# STM32U599xx register map
File version: 1.0
Registers are 32-bit, read-write, reset 0x0 unless marked. A register's access mark holds for its fields unless they carry their own. Offsets are from the block's base; [hi:lo] are bit positions; {n}, {i} and the like mark numbered series; 'fields as' and 'values as' point back to an identical list.

## COMP1 — Comparator
Base 0x46005400; alternate view of COMP12
Same registers: COMP2 0x46005404, COMP1_S 0x56005400 (alternate view of COMP12_S), COMP2_S 0x56005404
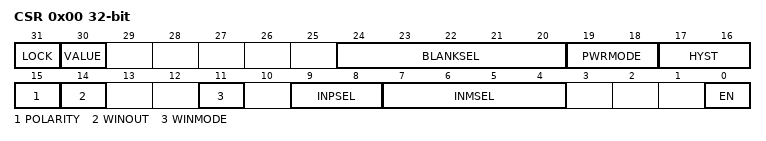
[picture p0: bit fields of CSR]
0x00 CSR — Comparator control and status register
  [31] LOCK — Comparator lock
  [30] VALUE — Comparator output level
  [24:20] BLANKSEL — Comparator blanking source
    0=NONE (Comparator output without blanking); 1=TIM1_OC5 (Comparator output blanking source TIM1 OC5 for COMP1 Instance); 2=TIM2_OC3 (Comparator output blanking source TIM2 OC3 for COMP1 Instance); 4=TIM3_OC3 (Comparator output blanking source TIM3 OC3 for COMP1 Instance)
  [19:18] PWRMODE — Comparator power mode
    0=HIGHSPEED (COMP power mode to high speed); 1=MEDIUMSPEED (COMP power mode to medium speed); 3=ULTRALOWPOWER (COMP power mode to ultra-low power)
  [17:16] HYST — Comparator input hysteresis
    0=NONE (No hysteresis); 1=LOW (Hysteresis level low); 2=MEDIUM (Hysteresis level medium); 3=HIGH (Hysteresis level high)
  [15] POLARITY — Comparator output polarity
    0=NONINVERTED (COMP output polarity is not inverted: comparator output is high when the plus (non-inverting) input is at a higher voltage than the minus (inverting) input); 1=INVERTED (COMP output polarity is inverted: comparator output is low when the plus (non-inverting) input is at a lower voltage than the minus (inverting) input)
  [14] WINOUT — Pair of comparators window output level. Bit intended to be used with COMP common instance (COMP_Common_TypeDef)
  [11] WINMODE — Pair of comparators window mode. Bit intended to be used with COMP common instance (COMP_Common_TypeDef)
  [9:8] INPSEL — Comparator input plus selection
    0=IO1 (Comparator input plus connected to IO1 (pin PC5 for COMP1, pin PB4 for COMP2)); 1=IO2 (Comparator input plus connected to IO2 (pin PB2 for COMP1, pin PB6 for COMP2)); 2=IO3 (Comparator input plus connected to IO3 (pin PA2 for COMP1))
  [7:4] INMSEL — Comparator input minus selection
    0=MINUS_1_4VREFINT (Comparator input minus connected to 1/4 VrefInt); 1=MINUS_1_2VREFINT (Comparator input minus connected to 1/2 VrefInt); 2=MINUS_3_4VREFINT (Comparator input minus connected to 3/4 VrefInt); 3=VREFINT (Comparator input minus connected to VrefInt); 4=DAC1_CH1 (Comparator input minus connected to DAC1 channel 1 (DAC_OUT1)); 5=DAC1_CH2 (Comparator input minus connected to DAC1 channel 2 (DAC_OUT2)); 6=IO1 (Comparator input minus connected to IO1 (pin PB1 for COMP1, pin PB3 for COMP2)); 7=IO2 (Comparator input minus connected to IO2 (pin PC4 for COMP1, pin PB7 for COMP2))
  [0] EN — Comparator enable

## VREFBUF
Base 0x46007400
Same registers: VREFBUF_S 0x56007400
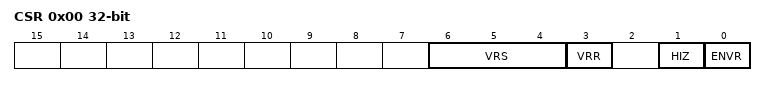
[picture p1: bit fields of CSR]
0x00 CSR — VREFBUF control and status register
  [6:4] VRS — Voltage reference scale
    {v}=SCALE{v} (Voltage reference scale {v} (VREF_OUT{v+1})) (v=0..3)
  [3] VRR — Voltage reference buffer ready
  [1] HIZ — High impedance mode
  [0] ENVR — Voltage reference buffer enable
0x04 CCR — VREFBUF calibration and control register
  [5:0] TRIM — TRIM[5:0] bits (Trimming code)

## EXTI — Asynch Interrupt/Event Controller (EXTI)
Base 0x46022000
Same registers: EXTI_S 0x56022000
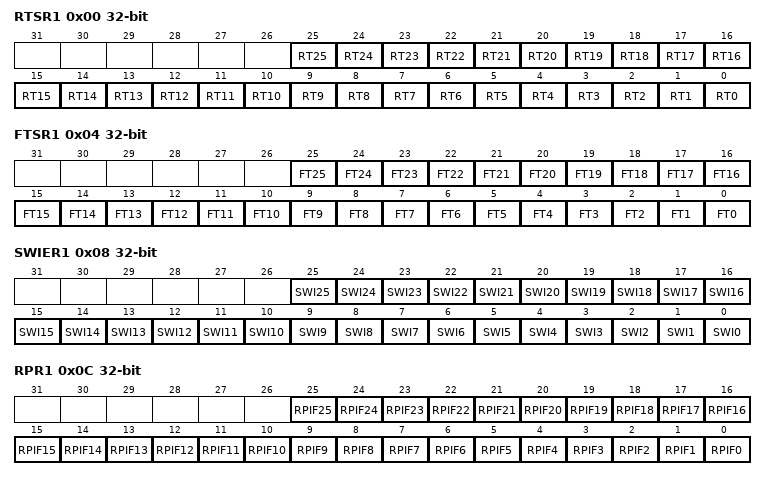
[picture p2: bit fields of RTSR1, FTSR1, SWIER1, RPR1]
0x00 RTSR1 — EXTI Rising Trigger Selection Register 1
  [25] RT25 — Rising trigger configuration for input line 24
  [n] RT{n} (n=0..24) — Rising trigger configuration for input line {n}
0x04 FTSR1 — EXTI Falling Trigger Selection Register 1
  [n] FT{n} (n=0..25) — Falling trigger configuration for input line {n}
0x08 SWIER1 — EXTI Software Interrupt event Register 1
  [n] SWI{n} (n=0..25) — Software Interrupt on line {n}
0x0C RPR1 — EXTI Rising Pending Register 1
  [n] RPIF{n} (n=0..25) — Rising Pending Interrupt Flag on line {n}
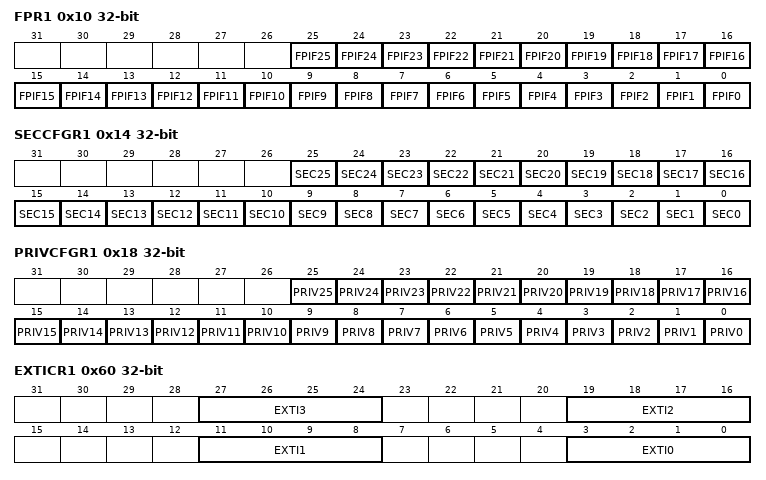
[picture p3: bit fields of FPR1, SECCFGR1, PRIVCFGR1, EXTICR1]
0x10 FPR1 — EXTI Falling Pending Register 1
  [n] FPIF{n} (n=0..25) — Falling Pending Interrupt Flag on line {n}
0x14 SECCFGR1 — EXTI Security Configuration Register 1
  [n] SEC{n} (n=0..25) — Security enable on line {n}
0x18 PRIVCFGR1 — EXTI Privilege Configuration Register 1
  [n] PRIV{n} (n=0..25) — Privilege enable on line {n}
0x60 EXTICR1 — EXIT External Interrupt Configuration Register, 0x60 -- 0x6C
  [8n+3:8n] EXTI{n} (n=0..3) — EXTI {n} configuration
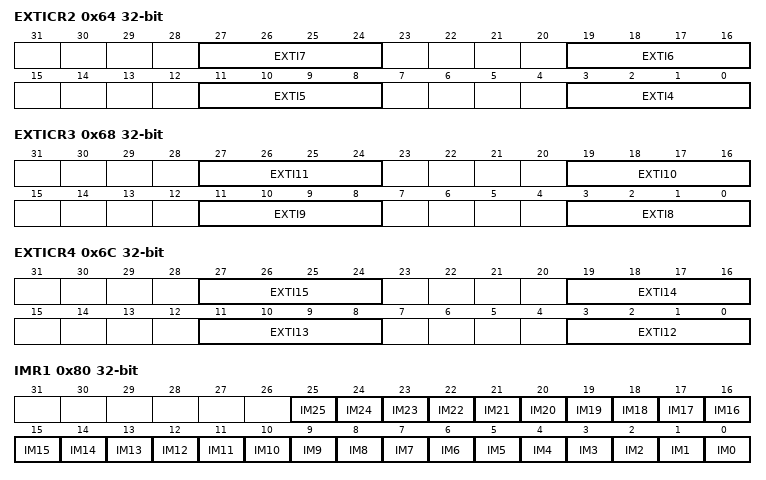
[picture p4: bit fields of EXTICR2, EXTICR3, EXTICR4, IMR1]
0x64 EXTICR2 — EXIT External Interrupt Configuration Register, 0x60 -- 0x6C
  [8n-29:8n-32] EXTI{n} (n=4..7) — EXTI {n} configuration
0x68 EXTICR3 — EXIT External Interrupt Configuration Register, 0x60 -- 0x6C
  [8n-61:8n-64] EXTI{n} (n=8..11) — EXTI {n} configuration
0x6C EXTICR4 — EXIT External Interrupt Configuration Register, 0x60 -- 0x6C
  [8n-93:8n-96] EXTI{n} (n=12..15) — EXTI {n} configuration
0x70 LOCKR — EXTI Lock Register
  [0] LOCK — Global security and privilege configuration registers lock
0x80 IMR1 — EXTI Interrupt Mask Register 1
  [n] IM{n} (n=0..25) — Interrupt Mask on line {n}
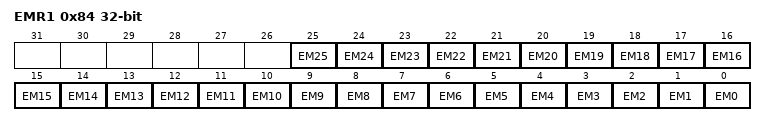
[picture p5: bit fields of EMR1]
0x84 EMR1 — EXTI Event Mask Register 1
  [n] EM{n} (n=0..25) — Event Mask on line {n}

## GTZC_TZIC2
Base 0x46023400
Same registers: GTZC_TZIC2_S 0x56023400
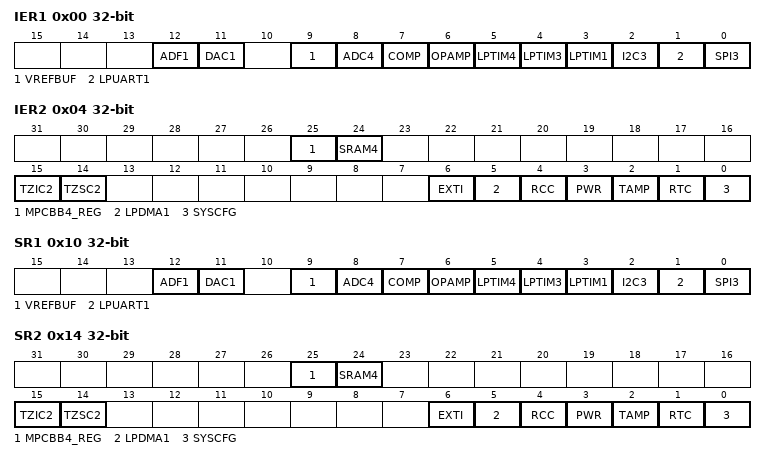
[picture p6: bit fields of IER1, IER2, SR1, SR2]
0x00 IER1 — TZIC interrupt enable register 1
  [12] ADF1, [11] DAC1, [9] VREFBUF, [8] ADC4, [7] COMP, [6] OPAMP, [5] LPTIM4, [4] LPTIM3, [3] LPTIM1, [2] I2C3, [1] LPUART1, [0] SPI3
0x04 IER2 — TZIC interrupt enable register 2
  [25] MPCBB4_REG, [24] SRAM4, [15] TZIC2, [14] TZSC2, [6] EXTI, [5] LPDMA1, [4] RCC, [3] PWR, [2] TAMP, [1] RTC, [0] SYSCFG
0x08 IER3 — TZIC interrupt enable register 3
0x0C IER4 — TZIC interrupt enable register 4
0x10 SR1 — TZIC status register 1
  fields as IER1
0x14 SR2 — TZIC status register 2
  fields as IER2
0x18 SR3 — TZIC status register 3
0x1C SR4 — TZIC status register 4
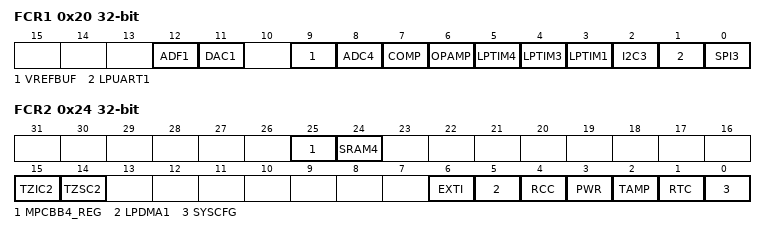
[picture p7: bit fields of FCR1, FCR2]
0x20 FCR1 — TZIC flag clear register 1
  fields as IER1
0x24 FCR2 — TZIC flag clear register 2
  fields as IER2
0x28 FCR3 — TZIC flag clear register 3
0x2C FCR4 — TZIC flag clear register 3

## DBGMCU — Debug MCU
Base 0xE0044000
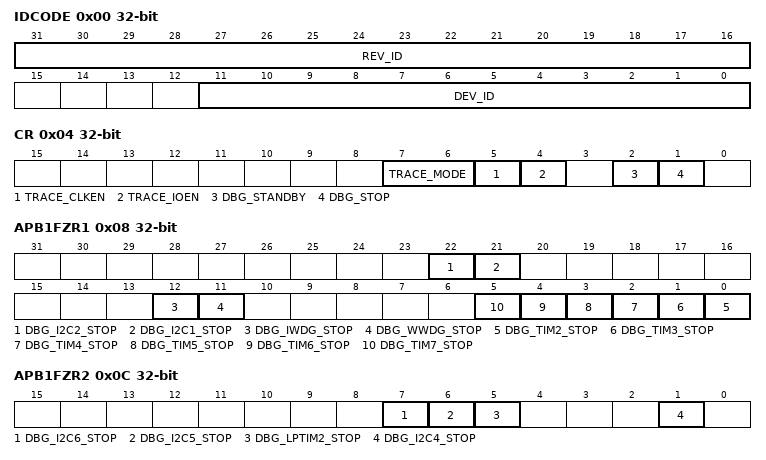
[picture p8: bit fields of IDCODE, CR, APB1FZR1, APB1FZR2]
0x00 IDCODE — MCU device ID code
  [31:16] REV_ID, [11:0] DEV_ID
0x04 CR — Debug MCU configuration register
  [7:6] TRACE_MODE, [5] TRACE_CLKEN, [4] TRACE_IOEN, [2] DBG_STANDBY, [1] DBG_STOP
0x08 APB1FZR1 — Debug MCU APB1 freeze register 1
  [22] DBG_I2C2_STOP, [21] DBG_I2C1_STOP, [12] DBG_IWDG_STOP, [11] DBG_WWDG_STOP, [n-2] DBG_TIM{n}_STOP (n=2..7)
0x0C APB1FZR2 — Debug MCU APB1 freeze register 2
  [7] DBG_I2C6_STOP, [6] DBG_I2C5_STOP, [5] DBG_LPTIM2_STOP, [1] DBG_I2C4_STOP
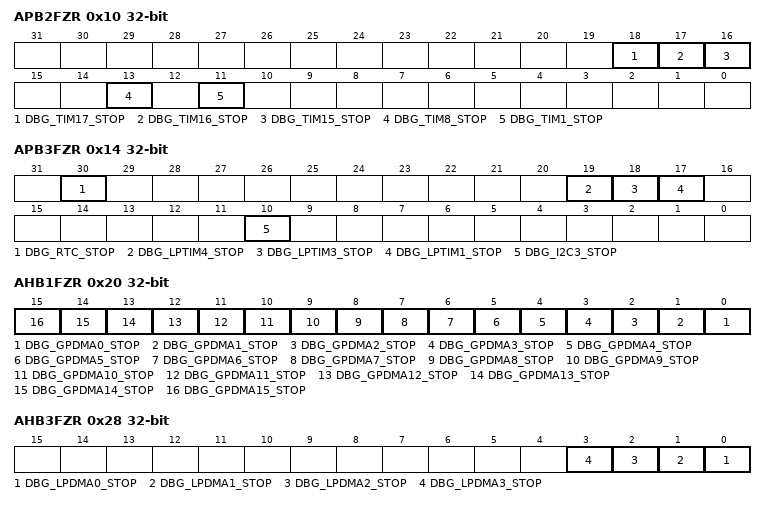
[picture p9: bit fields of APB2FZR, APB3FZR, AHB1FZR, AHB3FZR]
0x10 APB2FZR — Debug MCU APB2 freeze register
  [18] DBG_TIM17_STOP, [17] DBG_TIM16_STOP, [16] DBG_TIM15_STOP, [13] DBG_TIM8_STOP, [11] DBG_TIM1_STOP
0x14 APB3FZR — Debug MCU APB3 freeze register
  [30] DBG_RTC_STOP, [19] DBG_LPTIM4_STOP, [18] DBG_LPTIM3_STOP, [17] DBG_LPTIM1_STOP, [10] DBG_I2C3_STOP
0x20 AHB1FZR — Debug MCU AHB1 freeze register
  [n] DBG_GPDMA{n}_STOP (n=0..15)
0x28 AHB3FZR — Debug MCU AHB3 freeze register
  [n] DBG_LPDMA{n}_STOP (n=0..3)
